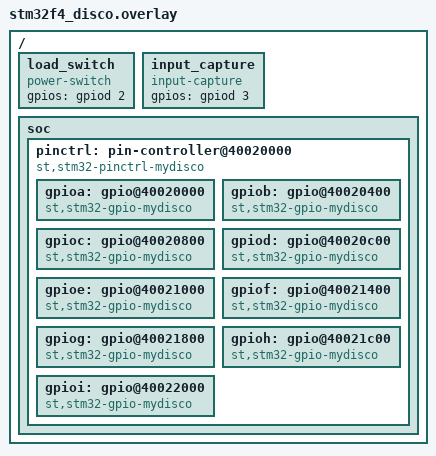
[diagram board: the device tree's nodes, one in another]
/*
 * Copyright (c) 2023 Martin Jäger / Libre Solar
 *
 * SPDX-License-Identifier: Apache-2.0
 */

/ {
	// chosen {
	// 	zephyr,shell-uart = &usart1;
	// };

	load_switch: load_switch {                                // <node label>:<node name> - create new node
		compatible = "power-switch";
		gpios = <&gpiod 2 GPIO_ACTIVE_HIGH>;                // define new pin PD2
	};

	input_capture: input_capture{
		compatible = "input-capture";
		gpios = <&gpiod 3 GPIO_ACTIVE_HIGH>;
	};

	soc{
		pinctrl: pin-controller@40020000{
			compatible = "st,stm32-pinctrl-mydisco";
			gpioa: gpio@40020000 {
				compatible = "st,stm32-gpio-mydisco";
			};
			gpiob: gpio@40020400 {
				compatible = "st,stm32-gpio-mydisco";
			};
			gpioc: gpio@40020800 {
				compatible = "st,stm32-gpio-mydisco";
			};
			gpiod: gpio@40020c00 {
				compatible = "st,stm32-gpio-mydisco";
			};
			gpioe: gpio@40021000 {
				compatible = "st,stm32-gpio-mydisco";
			};
			gpiof: gpio@40021400 {
				compatible = "st,stm32-gpio-mydisco";
			};
			gpiog: gpio@40021800 {
				compatible = "st,stm32-gpio-mydisco";
			};
			gpioh: gpio@40021c00 {
				compatible = "st,stm32-gpio-mydisco";
			};
			gpioi: gpio@40022000 {
				compatible = "st,stm32-gpio-mydisco";
			};
		};
	};
};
